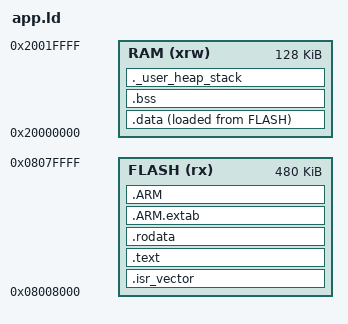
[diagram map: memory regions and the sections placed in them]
/* ============================================================================
 * Linker Script for STM32F446ZET6 Application (BigTreeTech Octopus)
 * Sectors 2 to 7: 480 KB (0x08008000 - 0x0807FFFF)
 * ============================================================================ */

ENTRY(Reset_Handler)

_estack = ORIGIN(RAM) + LENGTH(RAM); /* 0x20020000 */

MEMORY
{
    FLASH (rx)  : ORIGIN = 0x08008000, LENGTH = 480K
    RAM   (xrw) : ORIGIN = 0x20000000, LENGTH = 128K
}

SECTIONS
{
    .isr_vector :
    {
        . = ALIGN(4);
        KEEP(*(.isr_vector))
        . = ALIGN(4);
    } > FLASH

    .text :
    {
        . = ALIGN(4);
        *(.text)
        *(.text*)
        *(.glue_7)
        *(.glue_7t)
        *(.eh_frame)
        . = ALIGN(4);
        _etext = .;
    } > FLASH

    .rodata :
    {
        . = ALIGN(4);
        *(.rodata)
        *(.rodata*)
        . = ALIGN(4);
    } > FLASH

    .ARM.extab : { *(.ARM.extab* .gnu.linkonce.armextab.*) } > FLASH
    .ARM : {
        __exidx_start = .;
        *(.ARM.exidx*)
        __exidx_end = .;
    } > FLASH

    _sidata = LOADADDR(.data);

    .data :
    {
        . = ALIGN(4);
        _sdata = .;
        *(.data)
        *(.data*)
        . = ALIGN(4);
        _edata = .;
    } > RAM AT> FLASH

    .bss :
    {
        . = ALIGN(4);
        _sbss = .;
        __bss_start__ = _sbss;
        *(.bss)
        *(.bss*)
        *(COMMON)
        . = ALIGN(4);
        _ebss = .;
        __bss_end__ = _ebss;
    } > RAM

    /* Provide heap and stack symbols for standard libraries */
    ._user_heap_stack :
    {
        . = ALIGN(8);
        PROVIDE ( end = . );
        PROVIDE ( _end = . );
        . = . + 0x800; /* 2KB minimum heap reserve */
        . = ALIGN(8);
    } > RAM
}
